# psc3_p8_ppca register map
Vendor: Infineon Technologies; Series: PSC3_P8; File version: 1.0
CPU: CM33 r0p1, little endian, MPU, FPU, DSP, VTOR, 3 interrupt priority bits, 143 interrupts
Registers are 32-bit, read-write, reset 0x0 unless marked. A register's access mark holds for its fields unless they carry their own. Offsets are from the block's base; [hi:lo] are bit positions; lines under a group give offsets from that group; {n}, {i} and the like mark numbered series.

## PPCA_ATOPSS_ADC_GRP0
Base 0x43580000
Same registers: PPCA_ATOPSS_ADC_GRP1 0x43582000, PPCA_ATOPSS_ADC_GRP2 0x43584000, PPCA_ATOPSS_ADC_GRP3 0x43586000
0x00 SLICE group
  0x00 ADC group
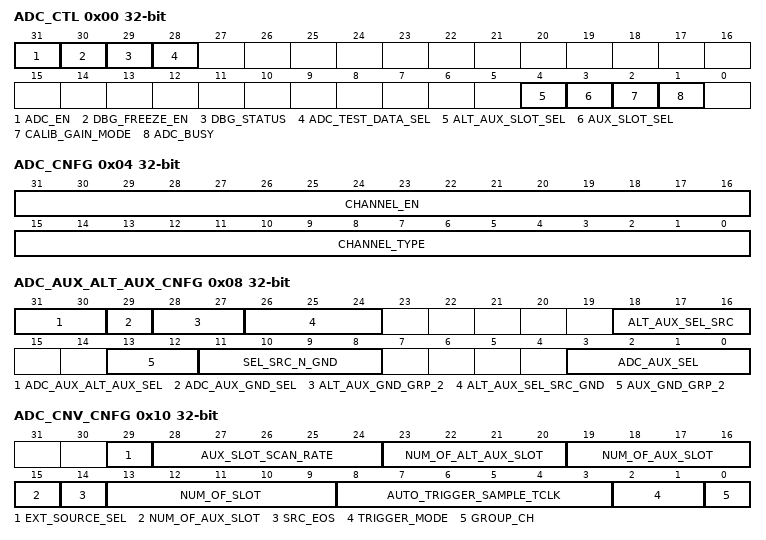
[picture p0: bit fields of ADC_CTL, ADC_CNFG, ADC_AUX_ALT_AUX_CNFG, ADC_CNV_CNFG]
    0x00 ADC_CTL — ADC Control Register
      [31] ADC_EN — ADC Enable: 1 = Enable 0 = Disable (whole ADC is in power down)
      [30] DBG_FREEZE_EN — Specifies the adc behavior in debug mode. '0': When ='0', ADC operation continues or resume '1': When ='1', ADC will complete the existing ADC conversion whether it is manual or auto mode
      [29] DBG_STATUS ro — Specifies whether ADC has enter into Debug state 1 = Yes 0 = No
      [28] ADC_TEST_DATA_SEL — Specifies the data is coming from ADC or from the ADC DATA Test register 1 = Data from ADC DATA Test Register 0 = Data from ADC
      [4] ALT_AUX_SLOT_SEL — Specifies the slot control scheme for the ALT AUX Channel 1 = Slot Control scheme for the ALT AUX Channel is enabled 0 = Slot control scheme for ALT AUX channel is disabled
      [3] AUX_SLOT_SEL — Specifies the slot control scheme for the AUX Channel 1 = Slot Control scheme for the AUX Channel is enabled 0 = Slot control scheme for AUX channel is disabled
      [2] CALIB_GAIN_MODE — CALIB_GAIN_MODE: (Please take not that this bit is not be used by customer. For internal use only) 1 = IP handle calibration and gain computation 0 = Subsystem handle calibration and gain computation
      [1] ADC_BUSY ro — ADC Busy: 1 = Conversion is in progress 0 = Idle
    0x04 ADC_CNFG — ADC Configuration Register
      [31:16] CHANNEL_EN — ADC Channel enable/disable, 0 = Disabled 1 = Enabled
      [15:0] CHANNEL_TYPE — ADC Channel type selection, 0= Single Ended 1= Differential
    0x08 ADC_AUX_ALT_AUX_CNFG — ADC Aux and ALT Aux Configuration Register
      [31:30] ADC_AUX_ALT_AUX_SEL — Specifes the ADC7,AUX_DATA,ALT_AUX_DATA 00 - ADC7 Path 01 - ADC7 Path 10 - AUX_DATA Path 11 - ALT_AUX_DATA Path
      [29] ADC_AUX_GND_SEL — Specifes the GND Selection 0 - Bit 11:8/Bit 26:24 Selection 1 - Bit 13:12/Bit 28:27 Selection
      [28:27] ALT_AUX_GND_GRP_2
        0=ALT_VSSA_ADC3; 1=ALT_VSSA_DCSG_GRP0; 2=ALT_VSSA_DCSG_GRP1; 3=ALT_VSSA_DCSG_GRP1_SP
      [26:24] ALT_AUX_SEL_SRC_GND — ADC_GND
        0=AIN3N_AIN11N_GND (ADC_GND); {v}=AI{v+1}_AI{v+8}_GND (ADC_GND) (v=1..7)
      [18:16] ALT_AUX_SEL_SRC — ADC ALT Auxliar Channels selection multiplexed with AI_AUX
        0=AIN3N_AIN11N (For ADC_GRP_0, it will be AIN3N. For ADC_GRP_3, it will be AIN11N); {v}=AI{v+1}_AI{v+8} (For ADC_GRP_0, it will be AI{v+1}. For ADC_GRP_3, it will be AI{v+8}) (v=1..7)
      [13:12] AUX_GND_GRP_2
        0=VSSA_ADC3; 1=VSSA_DCSG_GRP0; 2=VSSA_DCSG_GRP1; 3=VSSA_DCSG_GRP1_SP
      [11:8] SEL_SRC_N_GND — ADC Auxliar Channels selection multiplexed with channel 7 N Pin
        0=DAC_R2R_0_O_N (DAC_R2R_0N_0); 1=DAC_R2R_1_O_N (DAC_R2R_1N_0); 2=AI0_GND (ADC_GND); 3=AI1_GND (ADC_GND); 4=TSNS_GND (VSSA_AREF); 5=VSSA_AREF; 6=VDDA_DIV_2_GRP_0_GND (DCSG_GRP_0_GND); 7=VDDA_DIV_2_GRP_1_GND (DCSG_GRP_1_GND)
      [3:0] ADC_AUX_SEL — ADC Auxliar Channels selection multiplexed with channel 7 P Pin
        0=DAC_R2R_0_O (DAC_R2R_0 Output); 1=DAC_R2R_1_O (DAC_R2R_1 Output); 2=AI0; 3=AI1; 4=TSNS; 5=VREF; 6=VDDA_DIV_2_GRP_0 (VDDA Div 2 Voltage from DCSG_GRP_0); 7=VDDA_DIV_2_GRP_1 (VDDA Div 2 Voltage from DCSG_GRP_1)
    0x10 ADC_CNV_CNFG — ADC Conversion Configuration Register
      [29] EXT_SOURCE_SEL — EXT_SOURCE_SEL 0 - Is not part of the AUX and ALT_AUX channel slot control 1 - Is part of the AUX_ALT_AUX channel slot control. This means EXT_SOURCE_SEL channel is configured in the ADC_CH_CNFG0. When GROUP_CH=1 and TRIGGER_MODE = 01
      [28:24] AUX_SLOT_SCAN_RATE — To define how many time the channel will be converted before slot switches to the next AUX Channel 0x00 - 1 time 0x1F - 32 times
      [23:20] NUM_OF_ALT_AUX_SLOT — Number of ALT AUX Slot to be converted for each provided trigger when Group of Channel flag is set
      [19:15] NUM_OF_AUX_SLOT — Number of AUX Slot to be converted for each provided trigger when Group of Channel flag is set
      [14] SRC_EOS — Select Source of EOS (when in Manual Trigger mode). 0 = Internal EOS (from ADC CTRL FSM, aligned with the SOC trigger signal generated in PPCA_CLK domain resynchronized in the ATOP_CLK domain) 1 = External EOS (aligned with the SOC trigger signal generated in the PPCA_CLK domain)
      [13:9] NUM_OF_SLOT — Number of Slot to be converted for each provided trigger when Group of Channel flag is set. Do not set more than the maximum number of the NUM_CH of in the GRP ADC.
      [8:3] AUTO_TRIGGER_SAMPLE_TCLK — Number of system clock cycles for sampling on top of a minimum of 4 clock cycles (0+4). This is not applicable for Arbitary trigger mode. When AFE is used, AFE_CLOCK_RATIO will define the sample period
      [2:1] TRIGGER_MODE — Trigger Mode Selection 00 = Manual Trigger Mode 01 = Auto trigger Mode (Continuous Conversion) 10 = Arbitrary trigger Mode (Arbitrary Conversion - Based on the individual adc_soc_i[x])
      [0] GROUP_CH — Select between Single channel or Group of sequence of Channels to be converted at provided trigger 0 = Single Channel 1 = Group Channels
    0x14 ADC_SAMPLING_MASK
      [15:0] ADC_CH_SAMPLING_MASK — ADC Channel sampling Mask 1 = Mask Channel Sampling 0 = UnMask Channel Samplig
    0x18 ADC_TRIGGER — ADC Channel Trigger register
      [15:0] ADC_TRIGGER — ADC Channel Trigger for HW Trigger Mode, In Manual Mode, it is based on Ored(ADC_TRIGGER_15:ADC_TRIGGER_0) 1 = Trigger ADC conversion 0 = Do nothing
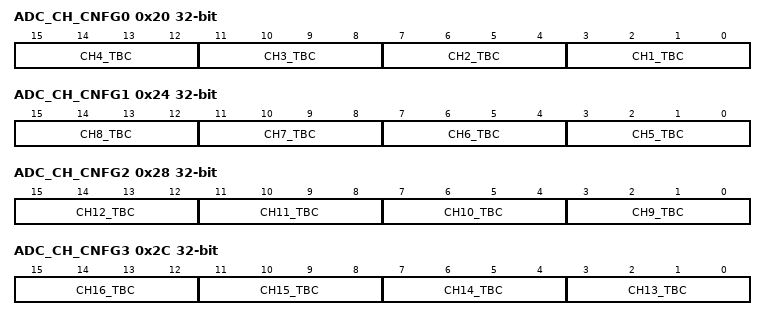
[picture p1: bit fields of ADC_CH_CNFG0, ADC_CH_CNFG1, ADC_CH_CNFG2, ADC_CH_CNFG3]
    0x20 ADC_CH_CNFG0 — ADC Channels group 0 to be converted Configurations registers
      [15:12] CH4_TBC — 4th Channel to be converted
      [11:8] CH3_TBC — 3rd Channel to be converted
      [7:4] CH2_TBC — 2nd Channel to be converted
      [3:0] CH1_TBC — 1st Channel to be converted. When AFE is enabled, CH1_TBC will be the default channel for AFE enabled case.
    0x24 ADC_CH_CNFG1 — ADC Channels group 1 to be converted Configurations registers
      [4n-17:4n-20] CH{n}_TBC (n=5..8) — {n}th Channel to be converted
    0x28 ADC_CH_CNFG2 — ADC Channels group 2 to be converted Configurations registers
      [4n-33:4n-36] CH{n}_TBC (n=9..12) — {n}th Channel to be converted
    0x2C ADC_CH_CNFG3 — ADC Channels group 3 to be converted Configurations registers
      [4n-49:4n-52] CH{n}_TBC (n=13..16) — {n}th Channel to be converted
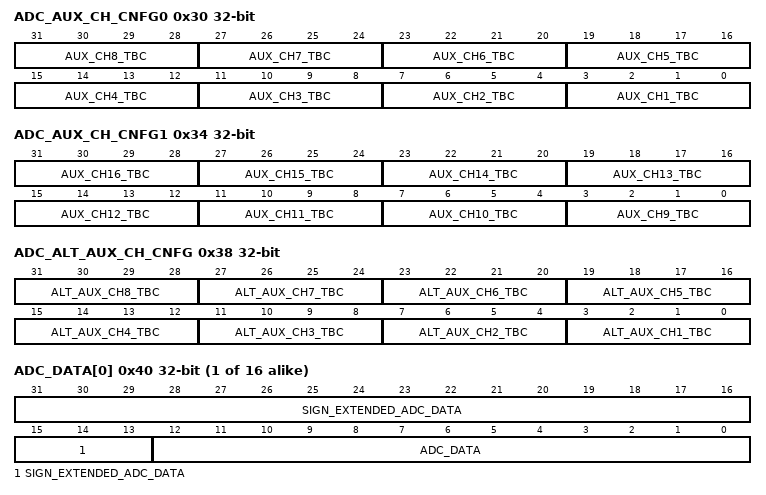
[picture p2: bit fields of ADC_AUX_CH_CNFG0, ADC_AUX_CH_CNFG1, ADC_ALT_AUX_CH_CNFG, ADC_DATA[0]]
    0x30 ADC_AUX_CH_CNFG0 — ADC Auxiliary Channels to be converted configuration registers
      [4n-1:4n-4] AUX_CH{n}_TBC (n=4..8) — {n}th Channel to be converted
      [11:8] AUX_CH3_TBC — 3rd Channel to be converted
      [7:4] AUX_CH2_TBC — 2nd Channel to be converted
      [3:0] AUX_CH1_TBC — 1st Channel to be converted
    0x34 ADC_AUX_CH_CNFG1 — ADC Auxiliary Channels to be converted configuration registers
      [4n-33:4n-36] AUX_CH{n}_TBC (n=9..16) — {n}th Channel to be converted
    0x38 ADC_ALT_AUX_CH_CNFG — ADC AUX Alternate Channel to be converted configuration register
      [4n-1:4n-4] ALT_AUX_CH{n}_TBC (n=4..8) — {n}th Channel to be converted
      [11:8] ALT_AUX_CH3_TBC — 3rd Channel to be converted
      [7:4] ALT_AUX_CH2_TBC — 2nd Channel to be converted
      [3:0] ALT_AUX_CH1_TBC — 1st Channel to be converted
    {0x40+4k} ADC_DATA[{k}] (k=0..15) ro — ADC Converted Data Channels
      [31:13] SIGN_EXTENDED_ADC_DATA — ADC DATA SIGN EXTENDED to faciliate CPU reading of 32 bits When ADC data is negative in the sign configuration, these bit will be 1. When ADC data is positive in the sign configuration or unsigned configuration, these bit will be 0.
      [12:0] ADC_DATA — ADC DATA Channel. ADC Data is only bit 11:0. Bit 12 is only when ADC RAW bit is set to 1 for bench testing purpose. In functional mode, ADC_CONVCTRL. RES_RAW bit is set to 0. When data is negative, bit 12 need be expressed as negative
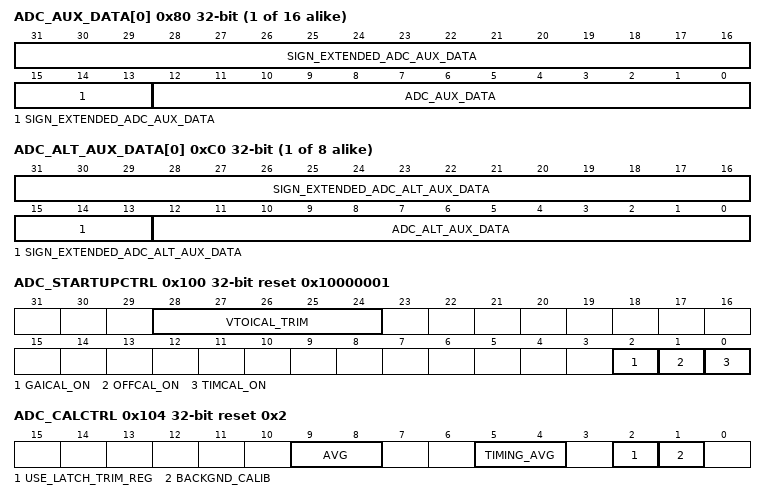
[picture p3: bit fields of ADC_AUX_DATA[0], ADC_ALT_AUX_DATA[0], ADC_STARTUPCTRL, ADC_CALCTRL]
    {0x80+4k} ADC_AUX_DATA[{k}] (k=0..15) ro — ADC Auxiliary Data Channels
      [31:13] SIGN_EXTENDED_ADC_AUX_DATA — ADC AUX DATA SIGN EXTENDED to faciliate CPU reading of 32 bits When ADC data is negative in the sign configuration, these bit will be 1. When ADC data is positive in the sign configuration or unsigned configuration, these bit will be 0.
      [12:0] ADC_AUX_DATA — ADC AUX DATA Channel
    {0xC0+4k} ADC_ALT_AUX_DATA[{k}] (k=0..7) ro — ADC Alternate Auxiliary Data Channels
      [31:13] SIGN_EXTENDED_ADC_ALT_AUX_DATA — ADC ALT AUX DATA SIGN EXTENDED to faciliate CPU reading of 32 bits When ADC data is negative in the sign configuration, these bit will be 1. When ADC data is positive in the sign configuration or unsigned configuration, these bit will be 0.
      [12:0] ADC_ALT_AUX_DATA — ADC ALT AUX DATA Channel
    0xE0 ADC_INTR — Interrupt request register
      [0] TR_ERROR write-1-clears — Trigger Error Event. Set to '1', when event is detected. Write with '1' to clear bit.
    0xE4 ADC_INTR_SET — Interrupt set request register
      [0] TR_ERROR write-1-sets — Write with '1' to set corresponding bit in interrupt request register.
    0xE8 ADC_INTR_MASK — Interrupt mask register
      [0] TR_ERROR — Mask bit for corresponding bit in interrupt request register.
    0xEC ADC_INTR_MASKED ro — Interrupt masked request register
      [0] TR_ERROR — Logical and of corresponding request and mask bits.
    0xF0 ADC_SIGN_UNSIGN_CNFG — ADC Channel Signed and Unsigned configuration Register
      [15:0] ADC_SIGN_UNSIGN_BITS — ADC Channel Unsigned Signed Configuration 0 - Unsigned 1 - Signed
    0xF4 AUX_SIGN_UNSIGN_CNFG — AUX Channel Signed and Unsigned configuration Register
      [15:0] AUX_SIGN_UNSIGN_BITS — AUX Channel Unsigned Signed Configuration 0 - Unsigned 1 - Signed
    0xF8 AUX_ALT_SIGN_UNSIGN_CNFG — AUX Alternate Channel Signed and Unsigned configuration Register
      [7:0] AUX_ALT_SIGN_UNSIGN_BITS — ALT_AUX Channel Unsigned Signed Configuration 0 - Unsigned 1 - Signed
    0x100 ADC_STARTUPCTRL reset 0x10000001 — SARADC STARTUP Control Register
      [28:24] VTOICAL_TRIM — vtoi trim calculated during functional tests and stored in flash/ROM(NVM). Loaded to this field during startup
      [2] GAICAL_ON — Gain sucal triggered during startup. Please take note that this bit should not be set to 1 for PSC3M8. Please refer to Section 5.2.1.4.6 of BROS
      [1] OFFCAL_ON — Offset sucal triggered during startup. Please take note that this bit should not be set to 1 for PSC3M8. Please refer to Section 5.2.1.4.6 of BROS
      [0] TIMCAL_ON — Timing sucal triggered during startup. Please take note that this bit should not be set to 0 for PSC3M8
    0x104 ADC_CALCTRL reset 0x2 — SARADC CALIBRATION Control Register
      [9:8] AVG — Determines averaging repetitions for calibration
        0=0: use 32 averaging repititions per calibration value; 1=1: use 64 averaging repititions per calibration value; 2=2: use 128 averaging repititions per calibration value; 3=3: use 2 averaging repititions per calibration value
      [5:4] TIMING_AVG — Determines the timing calibration averaging window for timing calibration
        0=Averaging length of 1; 1=Averaging length of 2; 2=Averaging length of 4; 3=Averaging length of 8
      [2] USE_LATCH_TRIM_REG — If set it will read the CALTIMING latch trim delay and use it instead of internal configuration during timing calibration. (for background and foreground)
      [1] BACKGND_CALIB — Background Timing Calibration is enabled, if disabled the timing can be manually set with the CAL Timing register.
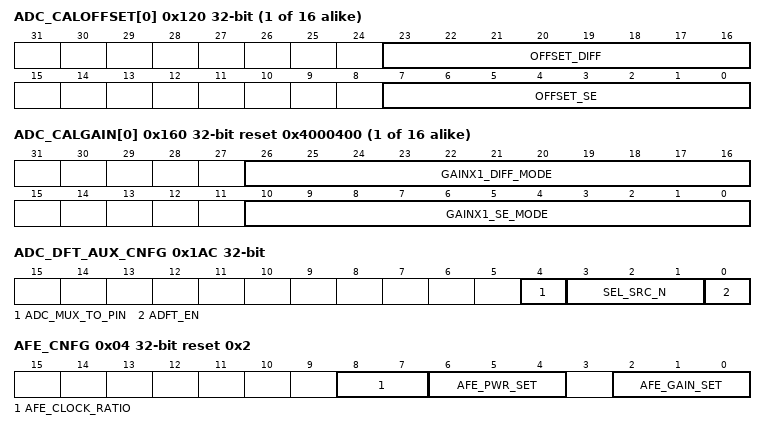
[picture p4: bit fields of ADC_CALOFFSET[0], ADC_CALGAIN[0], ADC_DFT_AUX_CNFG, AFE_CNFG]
    {0x120+4k} ADC_CALOFFSET[{k}] (k=0..15) — SARADC CAL offset per channel
      [23:16] OFFSET_DIFF — Signed offset calibration value for sampler in differential mode
      [7:0] OFFSET_SE — Signed offset calibration value for sampler in single ended mode
    {0x160+4k} ADC_CALGAIN[{k}] (k=0..15) reset 0x4000400 — SARADC GAIN CAL per channel
      [26:16] GAINX1_DIFF_MODE — Gain 1, passive and differential calibration value
      [10:0] GAINX1_SE_MODE — Gain 1, passive and single ended calibration value
    0x1AC ADC_DFT_AUX_CNFG — ADC DFT DATA Test register
      [4] ADC_MUX_TO_PIN — Connection from ADC Mux to AI0/AI1
      [3:1] SEL_SRC_N — ADC Auxliar Channels selection multiplexed with channel 7 N Pin
        0=External Source from Analog Input Pad; 1=DAC_R2R_0N_0; 2=DAC_R2R_1N_0; 3=ADC0_Gnd; 4=VSSA_AREF; 5=VSSA_ADC3; 6=VSSA_DCSG_GRP0; 7=VSSA_DCSG_GRP1
      [0] ADFT_EN — adc_adft_en 0: adft disabled 1: adft enabled. The converted data will be stored in ADC_DATA_7 register
  0x200 AFE group
    0x00 AFE_CTL
      [31] AFE_EN_0 — Enable/Disable AFE first stage 0 = Disable 1 = Enable
    0x04 AFE_CNFG reset 0x2
      [8:7] AFE_CLOCK_RATIO — AFE Clock Ratio Setting. Define the ADC MSPS setup based on ATOP_CLK relationshop
        0=MSPS: ATOP_CLK/4; 1=MSPS: ATOP_CLK/8; 2=MSPS: ATOP_CLK/16; 3=MSPS: ATOP_CLK/32
      [6:4] AFE_PWR_SET — AFE Power Setting. Select the AFE power setting
        0=HFLG_Default; 1=HFLG_LP; 2=HFLG_ULP; 3=LFHG; 4=Debug (100); 5=Debug (101); 6=Debug (110); 7=Debug (111)
      [2:0] AFE_GAIN_SET — AFE GAIN Settings. Select the AFE Gain setting
        0=OFF; 1=Gain of 3; 2=Gain of 6; 3=Gain of 12; 4=Gain of 24; 5=Gain of 24; 6=Gain of 12; 7=Gain of 12
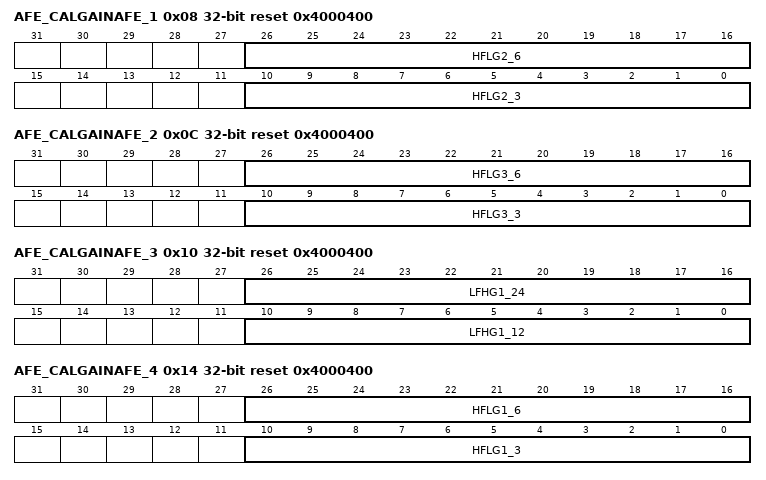
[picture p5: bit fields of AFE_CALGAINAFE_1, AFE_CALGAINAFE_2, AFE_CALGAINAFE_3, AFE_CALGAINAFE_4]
    0x08 AFE_CALGAINAFE_1 reset 0x4000400
      [26:16] HFLG2_6, [10:0] HFLG2_3
    0x0C AFE_CALGAINAFE_2 reset 0x4000400
      [26:16] HFLG3_6, [10:0] HFLG3_3
    0x10 AFE_CALGAINAFE_3 reset 0x4000400
      [26:16] LFHG1_24, [10:0] LFHG1_12
    0x14 AFE_CALGAINAFE_4 reset 0x4000400
      [26:16] HFLG1_6, [10:0] HFLG1_3
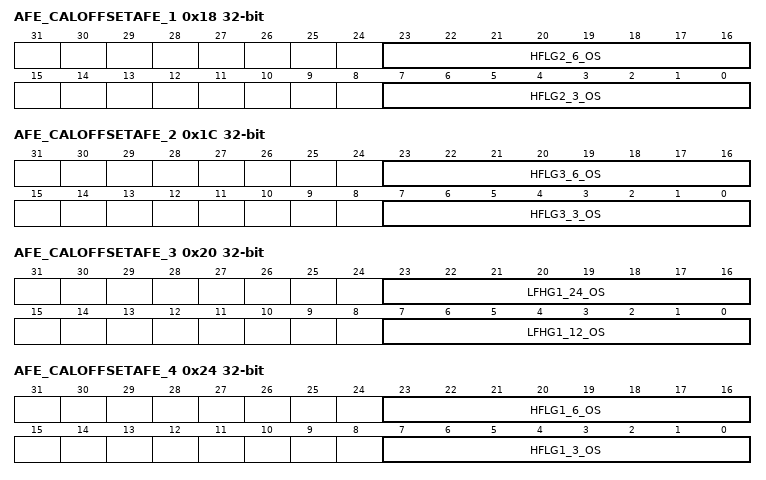
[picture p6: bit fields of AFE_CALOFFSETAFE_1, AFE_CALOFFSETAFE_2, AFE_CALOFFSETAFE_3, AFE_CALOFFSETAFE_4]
    0x18 AFE_CALOFFSETAFE_1
      [23:16] HFLG2_6_OS, [7:0] HFLG2_3_OS
    0x1C AFE_CALOFFSETAFE_2
      [23:16] HFLG3_6_OS, [7:0] HFLG3_3_OS
    0x20 AFE_CALOFFSETAFE_3
      [23:16] LFHG1_24_OS, [7:0] LFHG1_12_OS
    0x24 AFE_CALOFFSETAFE_4
      [23:16] HFLG1_6_OS, [7:0] HFLG1_3_OS
{0x1000+0x100*i} AFLT[{i}] (i=0..1) group
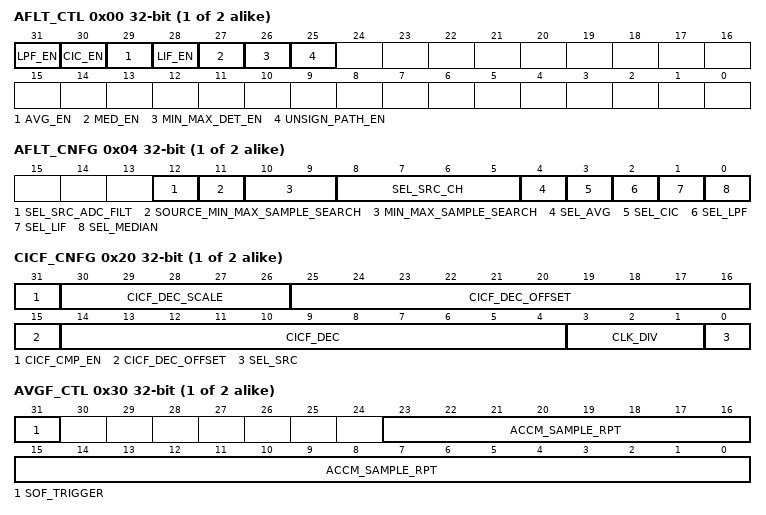
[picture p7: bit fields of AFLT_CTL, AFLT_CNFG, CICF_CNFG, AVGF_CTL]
  0x00 AFLT_CTL — Low Pass Filter Control Register
    [31] LPF_EN — Enable/Disable LP Filter. User shall avoid disable and enable different filter at the same write cycle. 0 = Disable (under reset) 1 = Enable
    [30] CIC_EN — Enable/Disable CIC Filter. User shall avoid disable and enable different filter at the same write cycle. 0 = Disable (under reset) 1 = Enable
    [29] AVG_EN — Enable/Disable AVG Filter. User shall avoid disable and enable different filter at the same write cycle. 0 = Disable (under reset) 1 = Enable
    [28] LIF_EN — Enable/Disable LIF Filter. User shall avoid disable and enable different filter at the same write cycle. 0 = Disable (under reset) 1 = Enable
    [27] MED_EN — Enable/Disable MED Filter. User shall avoid disable and enable different filter at the same write cycle. 0 = Disable (under reset) 1 = Enable
    [26] MIN_MAX_DET_EN — Enable/Disable MIN/MAX Detection Feature. User shall avoid disable and enable different filter at the same write cycle. 0 = Disable (under reset) 1 = Enable
    [25] UNSIGN_PATH_EN — Enable/Disable unsigned path to Filter module (Please take note that this bit shall be set to '0' for filter functional operation. Only set to '1' for by-pass mode all all filter which is used for testing purpose) 0 = Disable (under reset) 1 = Enable unsigned path
  0x04 AFLT_CNFG — ADC Filter Module Configuration register
    [12] SEL_SRC_ADC_FILT — Select source of the ADC data for Filter Module: Please take note one of the filter need to be enabled. 0 = Internal source 1 = External source from other ADC_GRP
    [11] SOURCE_MIN_MAX_SAMPLE_SEARCH — Configure the source of the ADC data stream. 0 = ADC Input 1= Median Filter
    [10:9] MIN_MAX_SAMPLE_SEARCH — Configure Min/Max sample search window (Search is trigger by min_max_trigger_i, search is restart upon read ADC_MIN_MAX register): 0 = Open 1 = 16 points 2 = 64 points 3 = 256 points
    [8:5] SEL_SRC_CH — Configure which ADC channel will be used as sourced of Filter Module: For ADC0 and ADC3, the number of channels is 8. For ADC1-2, the number of channels is 4 0000 = CH 0 0001 = CH 1 ... 1111= CH 15 Any value that is greater than the ADC's channels, the design will cap to the maximum channels when NUM_CH is less than 2^NUM_CH_LOG2
    [4] SEL_AVG — Bypass/Not Bypass AVG Filter 0 = not-bypass 1 = bypass
    [3] SEL_CIC — Bypass/Not Bypass CIC Filter 0 = not-bypass 1 = bypass
    [2] SEL_LPF — Bypass/Not Bypass LPF Filter 0 = not-bypass 1 = bypass
    [1] SEL_LIF — Bypass/Not Bypass LIF Filter 0 = not-bypass 1 = bypass
    [0] SEL_MEDIAN — Bypass/Not Bypass MED Filter 0 = not-bypass 1 = bypass
  0x10 LPF_ALFA — Low Pass Filter Bandwidth configuration Register
    [7:0] BW — Filter BW Configuration - Cutoff Freq
  0x14 LPF_DOUT ro — Low Pass Filter Data Output
    [15:0] LPF_DOUT — Filter Data Output. Data will not overflow. Cap at maximum
  0x20 CICF_CNFG — CIC3 Configuration register
    [31] CICF_CMP_EN — CIC Digital Compartor Enable (Compartor will be disabled when CIC_EN is disabled) 0 - Disable Compartor Feature 1 - Enable Compartor Feature
    [30:26] CICF_DEC_SCALE — CIC Scaling (0 - 31)
    [25:15] CICF_DEC_OFFSET — CIC Decimation offset
    [14:4] CICF_DEC — Decimation Factor (CIC Sample Rate / (Decimation Factor) For Signal input width of 16: Range of support is from 4 to 64 For signal input width of 1: Range of support is from 4 to 2047
    [3:1] CLK_DIV — Clock Divider for external source sampling PPCA_CLK/((1<<(CLK_DIV+2)) 0 - PPCA_CLK/4 1 - PPCA_CLK/8 2 - PPCA_CLK/16 3 - PPCA_CLK/32 4 - PPCA_CLK/64 5 - PPCA_CLK/128 6 - PPCA_CLK/256 7 - PPCA_CLK/512
    [0] SEL_SRC — Select Source of CIC Filter 0 = Internal (SD_CLK will be 0 for CIC_EN =0 or 1) 1 = External (SD_CLK will be provided, when SEL_SRC = 1 for CIC_EN =0 or 1)
  0x24 CICF_DOUT ro — CIC3 Filter Data Output
    [31:0] CICF_DOUT — Filter Data Output. Data will not overflow. Cap at maximum
  0x28 CICF_UB_TH — CIC3 Upper bound threshold register
    [31:16] CICF_UB_TH — Filter Upper Bound Threshold
  0x2C CICF_LB_TH — CIC3 Lower bound threshold register
    [31:16] CICF_LB_TH — Filter Lower Bound Threshold
  0x30 AVGF_CTL — Average Filter CTL register
    [31] SOF_TRIGGER — Start of filter trigger. This will reset the ACCUM_SAMPLE_RPT
    [23:0] ACCM_SAMPLE_RPT ro — Report the number of accumulated sample from the latest trigger
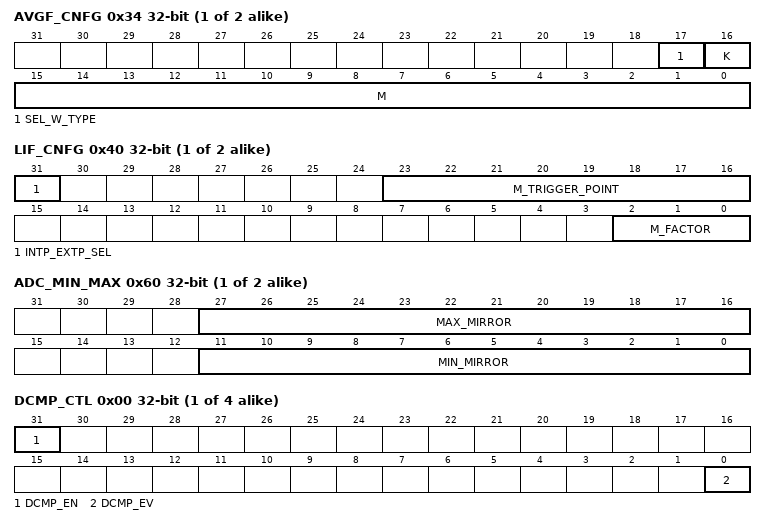
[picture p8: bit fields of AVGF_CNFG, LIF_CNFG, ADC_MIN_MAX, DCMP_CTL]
  0x34 AVGF_CNFG — Average Filter Configuration Register (N,M,K)
    [17] SEL_W_TYPE — Select Fix or Dynamic sample window: 0 = Fix (M defined by configuration) 1 = Dynamic (defined by SAMPLE_W signal - Level Signal )
    [16] K — Select Linear or Squared sample: 0 = Linear (K=1) in the Average Filter formula) 1 = Squared (K=2 in the Average filter formula)
    [15:0] M — Numbers of accumulated sample
  0x38 AVGF_DOUT ro — Average Filter Data Output
    [31:0] AVGF_DOUT — Filter Data Output. Data will not overflow. Cap at maximum
  0x40 LIF_CNFG — Linear Interpolator Filter Configuration register
    [31] INTP_EXTP_SEL — To select Intp/Extp 0 - Intp 1 - Extp
    [23:16] M_TRIGGER_POINT ro — To indicate the location of M_Trigger_point Value from 0 to 255
    [2:0] M_FACTOR — To define the maximum number of clock cycle between two SoC for the ADC Conversion 0 - 2 1 - 4 2 - 8 3 - 16 4 - 32 5 - 64 6 - 128 7 - 256
  0x44 LIF_DOUT ro — Linear Interpolator Filter Data Output
    [15:0] LIF_DOUT — Filter Data Output. Data will not overflow. Cap at maximum
  0x50 MED_CNFG — Median Filter Configuration register
    [15:0] CNFG_MED — MED Configuration - (Plan for Future)
  0x54 MED_DOUT ro — Median Filter Data Output
    [11:0] MED_DOUT — Filter Data Output. Data will not overflow. Cap at maximum
  0x60 ADC_MIN_MAX ro — ADC Min Max detect value Register
    [27:16] MAX_MIRROR — Max ADC data input stream value in the defined window
    [11:0] MIN_MIRROR — Min ADC data input stream value in the defined window
{0x1400+0x100*i} DCMP[{i}] (i=0..3) group
  0x00 DCMP_CTL
    [31] DCMP_EN — DCMP Enable: 1 = Enable 0 = Disable (reset asserted)
    [0] DCMP_EV ro — Report status of the current digital comparison when INV_DCMP_ENV_CNFG = 0 0 = input less or equal to threshold 1 = input above threshold
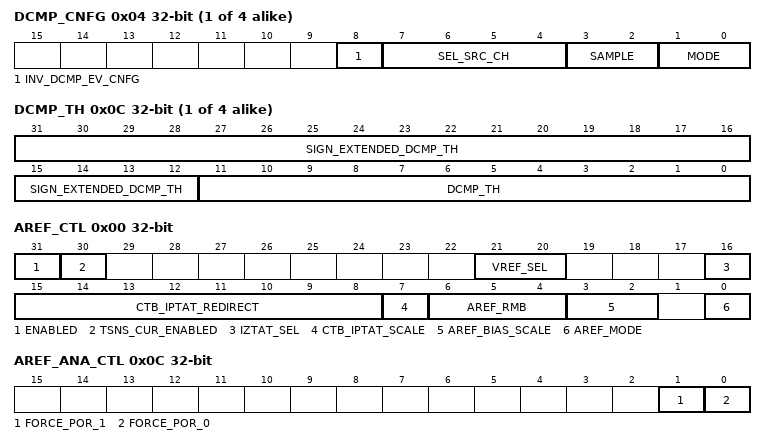
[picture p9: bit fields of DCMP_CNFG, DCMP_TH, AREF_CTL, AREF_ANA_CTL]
  0x04 DCMP_CNFG
    [8] INV_DCMP_EV_CNFG — INV_DCMP_EV 0: The immediate comparison result of mode 0 will not be inverted. 1: The immediate comparison result of mode 0 will be inverted.
    [7:4] SEL_SRC_CH — Configure which ADC channel will be used for comparison. For ADC0 and ADC3, the number of channels is 8. For ADC1-2, the number of channels is 4 0000 = CH 0 0001 = CH 1 ... 1111= CH 15 Any value that is greater than the ADC's channels, the design will cap to the maximum channels when NUM_CH is less than 2^NUM_CH_LOG2
    [3:2] SAMPLE — Configure average window: 0 = 4 points 1 = 16 points 2 = 64 points 3 = 256 points
    [1:0] MODE — DCMP Mode selection: 0 = immediate comparison 1 = accumulate of immediate comparison result (Seq of +1/-1). 2 = accumulate of immediate comparison result (Seq of +1/0) 3 = average comparison
  0x08 DCMP_TRIGGER
    [0] DCMP_TRIG — Trigger Comparison window when MODE = 3, 2, 1 and reset current computed value. 1 = trigger 0 = do nothing
  0x0C DCMP_TH
    [31:12] SIGN_EXTENDED_DCMP_TH ro — DCMP_TH SIGN EXTENDED to faciliate CPU 32 bits access When DCMP threshold data is negative for sign, these bit will be 1. When DCMP threshold data is positive in the sign or unsigned data is used, these bit will be 0.
    [11:0] DCMP_TH — DCMP Threshold can be expressed as signed or unsigned depending on the ADC Channel Signed and Unsigned configuration Register
  0x10 DCMP_ACC_TH
    [7:0] DCMP_ACC_TH — DCMP accumulate Threshold
0x1800 IDAC group
  0x00 IDAC_CTL
    [31] IDAC_EN — IDAC Enable: 1 = Enable 0 = Disable (reset asserted)
  0x04 IDAC_CNFG
    [3:0] MUX_SEL — IDAC Mode selection:
      0=MUX_SEL_Tri_state (No connection of the IDAC_MUX); 1=MUX_SEL_AI0 (Connect to AI0); 2=MUX_SEL_AI1 (Connect to AI1); 4=MUX_SEL_DCSG_0_VINP (Connect to DCSG<0>_vinp - Allow to do open circuit test.); 8=MUX_SEL_DCSG_0_VINN (Connect to DCSG<0>_vinn - Allow to do open circuit test)
0x1900 AREF group
  0x00 AREF_CTL — AREF control
    [31] ENABLED — AREF Enable
    [30] TSNS_CUR_ENABLED — Enable Bias current to Temp Sensor
    [21:20] VREF_SEL — bandgap voltage select control
      0=RSVD (N/A); 1=LOCAL (Use locally generated Vref); 2=EXTERNAL (Use externally supplied Vref (aref_ext_vref))
    [16] IZTAT_SEL
      0=RSVD (N/A); 1=LOCAL (Use locally generated 250nA)
    [15:8] CTB_IPTAT_REDIRECT
    [7] CTB_IPTAT_SCALE
    [6:4] AREF_RMB
    [3:2] AREF_BIAS_SCALE
    [0] AREF_MODE — Control bit to trade off AREF settling and noise performance
      0=NORMAL (Nominal noise normal startup mode (meets normal mode settling and noise specifications)); 1=FAST_START (High noise fast startup mode (meets fast mode settling and noise specifications))
  0x08 VDDA_STATUS ro — Analog Voltage Status
    [0] VDDA_OK — Read only status bit to determine the presence of VDDA 0: VDDA is below minimum threshold 1: VDDA is at or above minimum threhold
  0x0C AREF_ANA_CTL — Analog Control
    [1] FORCE_POR_1 — Override for Analog POR Hardware circuit. 0: (default) POR is controlled by analog hardware 1: Force POR negated (POR is an active low signal) NOTE: If this bit is set to 1, FORCE_POR_0 must be 0.
    [0] FORCE_POR_0 — Override for Analog POR Hardware circuit. 0: (default) POR is controlled by analog hardware 1: Force POR asserted (POR is an active low signal) If the MCPASS is not in use, set this bit to '1' to achieve the lowest level of IP leakage NOTE: If this bit is set to 1, FORCE_POR_1 must be 0.
  0x10 VREF_TRIM0 — VREF Trim bits
    [7:0] VREF_ABS_TRIM
  0x14 VREF_TRIM1 — VREF Trim bits
    [7:0] VREF_TEMPCO_TRIM
  0x18 VREF_TRIM2 — VREF Trim bits
    [7:0] VREF_CURV_TRIM
  0x1C VREF_TRIM3 — VREF Trim bits
    [3:0] VREF_ATTEN_TRIM — Obsolete
  0x20 IZTAT_TRIM0 — IZTAT Trim bits
    [7:0] IZTAT_ABS_TRIM
  0x24 IZTAT_TRIM1 — IZTAT Trim bits
    [7:0] IZTAT_TC_TRIM — IZTAT temperature correction trim (RMB) 0x00 : No IZTAT temperature correction 0xFF : Maximum IZTAT temperature correction As this is a Risk Mitigation Register, it should be loaded with 0x08.
  0x28 IPTAT_TRIM0 — IPTAT Trim bits
    [3:0] IPTAT_CORE_TRIM — IPTAT trim 0x0 : Minimum IPTAT current (~150nA at room) 0xF : Maximum IPTAT current (~350nA at room)
  0x2C IPTAT_TRIM1 — 0
    [3:0] IPTAT_CTBM_TRIM — CTMB PTAT Current Trim 0x0 : Minimum CTMB IPTAT Current (~875nA) 0xF : Maximum CTMB IPTAT Current (~1.1uA)
  0x30 ICTAT_TRIM0 — ICTAT Trim bits
    [3:0] ICTAT_TRIM — ICTAT trim 0x00 : Minimum ICTAT current (~150nA at room) 0x0F : Maximum ICTAT current (~350nA at room)
0x1A00 GPI group
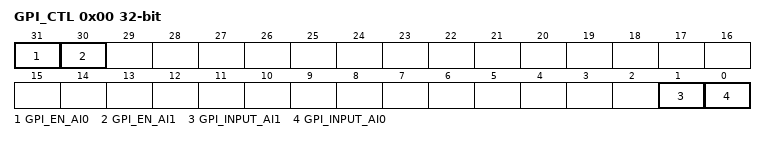
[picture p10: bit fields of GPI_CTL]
  0x00 GPI_CTL
    [31] GPI_EN_AI0 — GPI Enable for AI0: 1 = Enable 0 = Disable (reset asserted)
    [30] GPI_EN_AI1 — GPI Enable for AI1: 1 = Enable 0 = Disable (reset asserted)
    [1] GPI_INPUT_AI1 ro — Reflects input status of the AI1 0 = Low Level 1 = High Level
    [0] GPI_INPUT_AI0 ro — Reflects input status of the AI0 0 = Low Level 1 = High Level
